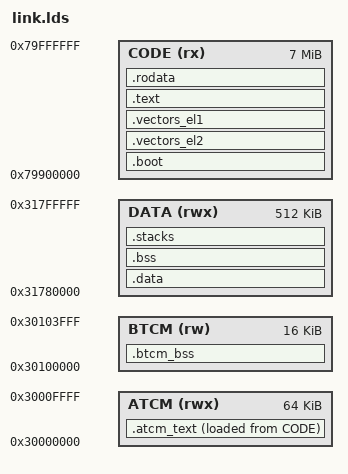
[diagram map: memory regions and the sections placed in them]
/***************************************************************************
 * Copyright (c) 2026 Eclipse ThreadX contributors
 *
 * This program and the accompanying materials are made available under the
 * terms of the MIT License which is available at
 * https://opensource.org/licenses/MIT.
 *
 * AI Disclosure: This file was largely AI-generated by Claude Code (Opus 5).
 * The AI-generated portions may be considered public domain (CC0-1.0)
 * and not subject to the project's licence. The human contributor has
 * reviewed and verified that the code is correct.
 *
 * SPDX-License-Identifier: MIT and CC0-1.0
 **************************************************************************/

/* Link map for the NXP S32Z280-594EVB, RTU0 core 0.
 *
 * Code goes to the RTU code SRAM at its instruction-fetch address, 0x79900000,
 * which is also where the core resets: MC_ME_PRTN0_CORE0_ADDR reads 0x79900000
 * on this board, so a debugger-loaded image needs no relocation to be reached
 * by the reset vector.  That window is writable over the debug AXI port even
 * though NXP's debugger memory map declares it read-only, so plain `load`
 * works and no LMA alias is required.  A flash-booted image is different: it
 * would have to be written through the data alias at 0x32100000.
 *
 * Data, bss and the per-mode stacks go to the RTU-local data SRAM at
 * 0x31780000.  Keeping them out of the code SRAM avoids the boundary problem
 * the FVP build hit, where an aligned .data start straddled the code/data
 * split, and RTU-local traffic does not leave the RTU.
 *
 * The TCMs are deliberately unused: they are not accessible at reset until
 * their region registers are programmed, so nothing needed for early boot can
 * live there.
 */

__hyp_stack_size__ = 0x0800;
__svc_stack_size__ = 0x1000;
__irq_stack_size__ = 0x0800;
__fiq_stack_size__ = 0x0400;
__abt_stack_size__ = 0x0400;
__und_stack_size__ = 0x0400;
__sys_stack_size__ = 0x0800;

MEMORY
{
    CODE (rx)  : ORIGIN = 0x79900000, LENGTH = 0x00700000    /* 7 MB   */
    /* ATCM.  entry.S programmes IMP_ATCMREGIONR to this base and enables the
       bank before anything runs from it, and mpu.c maps it executable.  Code
       placed here runs at full core speed with one wait state, where CODE is
       RTU code RAM and runs at half the core frequency (S32Z2 RM 6.3.6).  */
    ATCM (rwx) : ORIGIN = 0x30000000, LENGTH = 0x00010000    /* 64 KB  */
    /* BTCM.  16 KB at zero wait states, enabled by entry.S, and preloaded there
       as well because ECC means a location must be written before it is read.
       Used for data that wants deterministic access without depending on a
       cache -- an enabled TCM is never cached.  */
    BTCM (rw)  : ORIGIN = 0x30100000, LENGTH = 0x00004000    /* 16 KB  */
    DATA (rwx) : ORIGIN = 0x31780000, LENGTH = 0x00080000    /* 512 KB: DRAM0 + DRAM1, both full core speed */
}

ENTRY(_start)

SECTIONS
{
    /* .text.boot must come FIRST: MC_ME_PRTN0_CORE0_ADDR is 0x79900000 on
     * this board, so whatever lands at the start of CODE is what the core
     * executes out of reset, and that has to be _start.  It must also be a
     * T32 instruction, since the core resets in Thumb state.  The vector
     * tables need alignment but not a fixed address, because HVBAR and VBAR
     * are programmed at run time -- so they follow rather than lead.
     */
    /* No ALIGN() address expression on any output section below.  Written as
     * "<name> ALIGN(n) : { }" the ALIGN is the section's *address*, evaluated
     * from a location counter that starts at zero, and it silently overrides
     * "> CODE" -- every section then lands near address 0 and the link fails
     * with "not within region".  The FVP script uses that form harmlessly only
     * because its region starts at 0x00000000.  Alignment comes from the input
     * sections (the vector tables carry .align 5) or from an explicit
     * ". = ALIGN(n);" inside the braces.
     */
    .boot :
    {
        KEEP(*(.text.boot))
    } > CODE

    .vectors_el2 :
    {
        KEEP(*(.vectors_el2))
    } > CODE

    .vectors_el1 :
    {
        KEEP(*(.vectors_el1))
    } > CODE

    .text :
    {
        *(.text*)
        *(.glue_7)
        *(.glue_7t)
    } > CODE

    /* Code that runs from tightly-coupled memory.  Loaded into CODE and copied
       to ATCM by atcm_copy_text() before it is called, because ECC is enabled
       on this part and a TCM location must be written before it is read
       (Cortex-R52 TRM 6.2.2).  The copy uses 64-bit stores for the same
       reason: ATCM requires them where BTCM and CTCM accept 32-bit.

       ALIGN(8) at both ends so the copy can move whole 64-bit units without a
       tail case, which is what keeps the ECC requirement satisfied for every
       location written.  */

    .atcm_text : ALIGN(8)
    {
        __atcm_text_start__ = .;
        *(.atcm_text*)
        . = ALIGN(8);
        __atcm_text_end__ = .;
    } > ATCM AT> CODE

    __atcm_text_load__ = LOADADDR(.atcm_text);

    .rodata :
    {
        *(.rodata*)
        . = ALIGN(4);
        __code_end__ = .;
    } > CODE

    .data :
    {
        . = ALIGN(8);
        __data_start__ = .;
        *(.data*)
        . = ALIGN(8);
        __data_end__ = .;
    } > DATA

    /* Data placed in BTCM.  NOLOAD: nothing is copied in, and entry.S has
       already written every location in the bank to establish ECC check bits,
       so anything here is safe to read before it is written by the program.  */

    .btcm_bss (NOLOAD) : ALIGN(8)
    {
        __btcm_bss_start__ = .;
        *(.btcm_bss*)
        . = ALIGN(8);
        __btcm_bss_end__ = .;
    } > BTCM

    .bss (NOLOAD) :
    {
        . = ALIGN(8);
        __bss_start__ = .;
        *(.bss*)
        *(COMMON)
        . = ALIGN(8);
        __bss_end__ = .;
    } > DATA

    /* Per-mode stacks.  Each mode needs its own on an R-profile core: an
     * exception taken while a handler is running would otherwise reuse the
     * interrupted mode's stack pointer.
     */
    .stacks (NOLOAD) :
    {
        . = ALIGN(8);
        . = . + __hyp_stack_size__;
        __hyp_stack_top = .;
        . = ALIGN(8);
        . = . + __svc_stack_size__;
        __svc_stack_top = .;
        . = ALIGN(8);
        . = . + __irq_stack_size__;
        __irq_stack_top = .;
        . = ALIGN(8);
        . = . + __fiq_stack_size__;
        __fiq_stack_top = .;
        . = ALIGN(8);
        . = . + __abt_stack_size__;
        __abt_stack_top = .;
        . = ALIGN(8);
        . = . + __und_stack_size__;
        __und_stack_top = .;
        . = ALIGN(8);
        . = . + __sys_stack_size__;
        __sys_stack_top = .;
    } > DATA

    /* Both spellings: _tx_initialize_low_level publishes the first free
       address to tx_application_define from _end, while C library conventions
       use end.  */

    PROVIDE(end = .);
    PROVIDE(_end = .);
}
